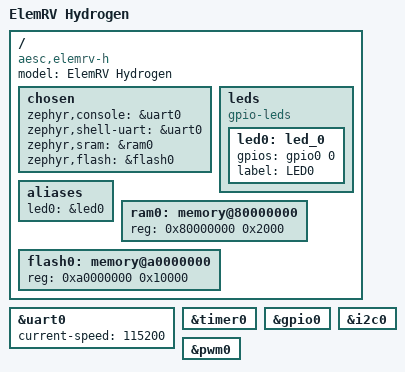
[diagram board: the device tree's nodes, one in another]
/*
 * SPDX-License-Identifier: Apache-2.0
 *
 * ElemRV Hydrogen board device tree.
 * VexRiscv RV32IC @ 50 MHz, 8 KB SRAM, 64 KB Flash (XIP).
 */

/dts-v1/;

#include <riscv32-elemrv-vexriscv.dtsi>
#include <zephyr/dt-bindings/gpio/gpio.h>

/ {
	model = "ElemRV Hydrogen";
	compatible = "aesc,elemrv-h";

	chosen {
		zephyr,console = &uart0;
		zephyr,shell-uart = &uart0;
		zephyr,sram = &ram0;
		zephyr,flash = &flash0;
	};

	leds {
		compatible = "gpio-leds";
		led0: led_0 {
			gpios = <&gpio0 0 GPIO_ACTIVE_HIGH>;
			label = "LED0";
		};
	};

	aliases {
		led0 = &led0;
	};

	ram0: memory@80000000 {
		device_type = "memory";
		reg = <0x80000000 0x2000>;
	};

	flash0: memory@a0000000 {
		reg = <0xa0000000 0x10000>;
	};
};

&uart0 {
	status = "okay";
	current-speed = <115200>;
};

&timer0 {
	status = "okay";
};

&gpio0 {
	status = "okay";
};

&i2c0 {
	status = "okay";
};

&pwm0 {
	status = "okay";
};
